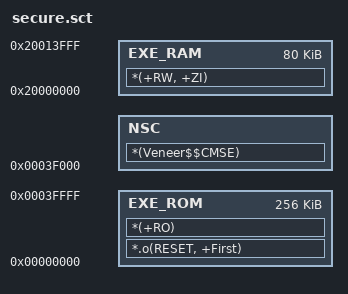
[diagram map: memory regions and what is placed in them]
LR_ROM 0x0
{
    EXE_ROM +0 0x40000
    {
        *.o(RESET, +First)
        *(+RO)
    }
    
    EXE_RAM 0x20000000 0x14000
    {
        *(+RW, +ZI)
    }
	
}

NSC_ROM 0x3f000 0x1000-144
{
    NSC +0
    {
		*(Veneer$$CMSE)
    }
}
